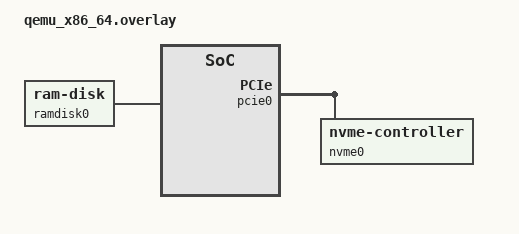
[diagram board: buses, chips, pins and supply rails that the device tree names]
/* SPDX-License-Identifier: Apache-2.0 */

#include <zephyr/dt-bindings/pcie/pcie.h>

/ {
	pcie0 {
		nvme0: nvme0 {
			compatible = "nvme-controller";

			vendor-id = <0x1B36>;
			device-id = <0x0010>;

			status = "okay";
		};
	};

	ramdisk0 {
		compatible = "zephyr,ram-disk";
		disk-name = "RAM";
		sector-size = <512>;
		sector-count = <192>;
	};
};
